VERSION ""

NS_ :

BS_:

BU_:

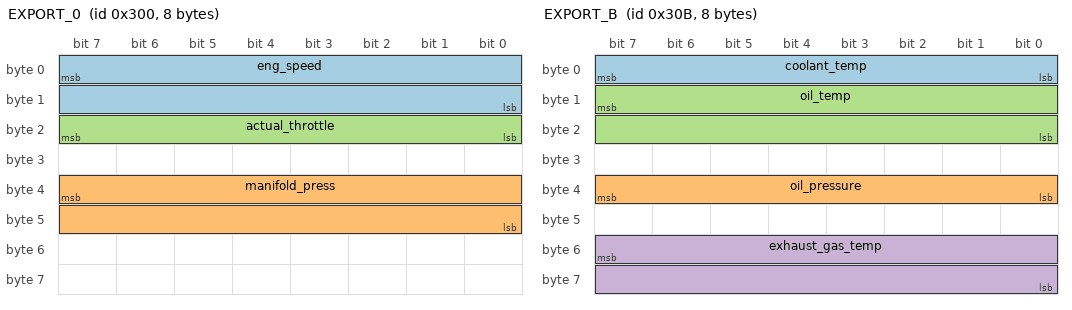
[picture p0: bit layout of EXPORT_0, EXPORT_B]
BO_ 768 EXPORT_0: 8 Vector__XXX
 SG_ eng_speed : 7|16@0+ (1,0) [0|0] "rpm" Vector__XXX
 SG_ manifold_press : 39|16@0+ (1,0) [0|0] "mBar" Vector__XXX
 SG_ actual_throttle : 23|8@0+ (0.00392156862745,0) [0|0] "n%" Vector__XXX
BO_ 779 EXPORT_B: 8 Vector__XXX
 SG_ coolant_temp : 7|8@0+ (1.12941176471,14) [0|0] "F" Vector__XXX
 SG_ oil_pressure : 39|8@0+ (0.580152,0) [0|0] "PSI" Vector__XXX
 SG_ oil_temp : 15|16@0+ (1.8,32) [0|0] "F" Vector__XXX
 SG_ exhaust_gas_temp : 55|16@0+ (1.8,32) [0|0] "F" Vector__XXX
BO_ 771 EXPORT_3: 8 Vector__XXX
 SG_ fuel_rail_pressure : 55|16@0- (1,0) [0|0] "Bar" Vector__XXX
BO_ 776 EXPORT_8: 8 Vector__XXX
 SG_ battery_bus_voltage : 7|16@0+ (0.0175953079179,0) [0|0] "0 = 0V, 1023 = 18V" Vector__XXX

VAL_ 0 CS 1 "Start" 2 "Stop" 128 "EnterPreOperational" 129 "ResetNode" 130 "ResetCommunication" ;
